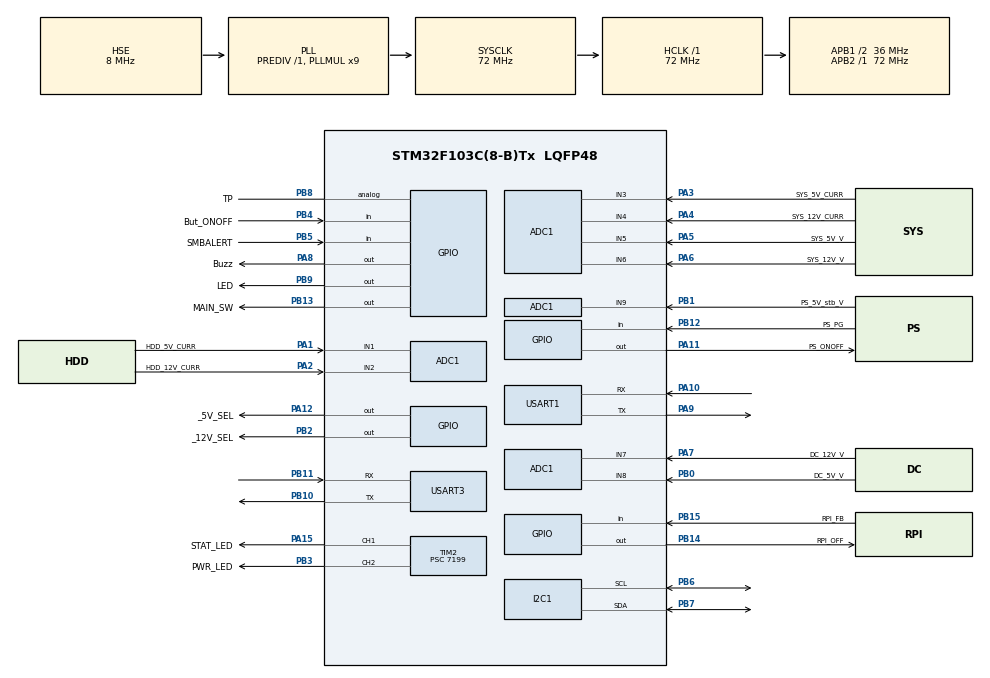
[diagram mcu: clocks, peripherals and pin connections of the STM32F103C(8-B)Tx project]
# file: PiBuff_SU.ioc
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ADC1.Channel-0\#ChannelRegularConversion=ADC_CHANNEL_TEMPSENSOR
ADC1.Channel-1\#ChannelRegularConversion=ADC_CHANNEL_1
ADC1.Channel-2\#ChannelRegularConversion=ADC_CHANNEL_2
ADC1.Channel-3\#ChannelRegularConversion=ADC_CHANNEL_3
ADC1.Channel-4\#ChannelRegularConversion=ADC_CHANNEL_4
ADC1.Channel-5\#ChannelRegularConversion=ADC_CHANNEL_5
ADC1.Channel-6\#ChannelRegularConversion=ADC_CHANNEL_6
ADC1.Channel-7\#ChannelRegularConversion=ADC_CHANNEL_7
ADC1.Channel-8\#ChannelRegularConversion=ADC_CHANNEL_8
ADC1.Channel-9\#ChannelRegularConversion=ADC_CHANNEL_9
ADC1.ContinuousConvMode=ENABLE
ADC1.NbrOfConversion=10
ADC1.NbrOfConversionFlag=1
ADC1.Rank-0\#ChannelRegularConversion=1
ADC1.Rank-1\#ChannelRegularConversion=2
ADC1.Rank-2\#ChannelRegularConversion=3
ADC1.Rank-3\#ChannelRegularConversion=4
ADC1.Rank-4\#ChannelRegularConversion=5
ADC1.Rank-5\#ChannelRegularConversion=6
ADC1.Rank-6\#ChannelRegularConversion=7
ADC1.Rank-7\#ChannelRegularConversion=8
ADC1.Rank-8\#ChannelRegularConversion=9
ADC1.Rank-9\#ChannelRegularConversion=10
ADC1.SamplingTime-0\#ChannelRegularConversion=ADC_SAMPLETIME_239CYCLES_5
ADC1.SamplingTime-1\#ChannelRegularConversion=ADC_SAMPLETIME_1CYCLE_5
ADC1.SamplingTime-2\#ChannelRegularConversion=ADC_SAMPLETIME_1CYCLE_5
ADC1.SamplingTime-3\#ChannelRegularConversion=ADC_SAMPLETIME_1CYCLE_5
ADC1.SamplingTime-4\#ChannelRegularConversion=ADC_SAMPLETIME_1CYCLE_5
ADC1.SamplingTime-5\#ChannelRegularConversion=ADC_SAMPLETIME_1CYCLE_5
ADC1.SamplingTime-6\#ChannelRegularConversion=ADC_SAMPLETIME_1CYCLE_5
ADC1.SamplingTime-7\#ChannelRegularConversion=ADC_SAMPLETIME_1CYCLE_5
ADC1.SamplingTime-8\#ChannelRegularConversion=ADC_SAMPLETIME_1CYCLE_5
ADC1.SamplingTime-9\#ChannelRegularConversion=ADC_SAMPLETIME_1CYCLE_5
ADC1.master=1
Dma.ADC1.0.Direction=DMA_PERIPH_TO_MEMORY
Dma.ADC1.0.Instance=DMA1_Channel1
Dma.ADC1.0.MemDataAlignment=DMA_MDATAALIGN_WORD
Dma.ADC1.0.MemInc=DMA_MINC_ENABLE
Dma.ADC1.0.Mode=DMA_CIRCULAR
Dma.ADC1.0.PeriphDataAlignment=DMA_PDATAALIGN_WORD
Dma.ADC1.0.PeriphInc=DMA_PINC_DISABLE
Dma.ADC1.0.Priority=DMA_PRIORITY_LOW
Dma.Request0=ADC1
Dma.Request1=USART3_TX
Dma.USART3_TX.1.Direction=DMA_MEMORY_TO_PERIPH
Dma.USART3_TX.1.Instance=DMA1_Channel2
Dma.USART3_TX.1.MemDataAlignment=DMA_MDATAALIGN_BYTE
Dma.USART3_TX.1.MemInc=DMA_MINC_ENABLE
Dma.USART3_TX.1.Mode=DMA_NORMAL
Dma.USART3_TX.1.PeriphDataAlignment=DMA_PDATAALIGN_BYTE
Dma.USART3_TX.1.PeriphInc=DMA_PINC_DISABLE
Dma.USART3_TX.1.Priority=DMA_PRIORITY_LOW
I2C1.I2C_Mode=I2C_Fast
Mcu.Family=STM32F1
Mcu.Name=STM32F103C(8-B)Tx
Mcu.Package=LQFP48
NVIC.DMA1_Channel1_IRQn=true\:0\:0\:false\:false\:true\:false\:true
NVIC.DMA1_Channel2_IRQn=true\:0\:0\:false\:false\:true\:false\:true
NVIC.PriorityGroup=NVIC_PRIORITYGROUP_4
NVIC.RCC_IRQn=true\:0\:0\:false\:false\:true\:true\:false
NVIC.TIM2_IRQn=true\:0\:0\:false\:false\:true\:true\:true
NVIC.USART1_IRQn=true\:0\:0\:false\:false\:true\:true\:true
NVIC.USART3_IRQn=true\:0\:0\:false\:false\:true\:true\:true
PA0-WKUP.Mode=SYS_WakeUp0
PA0-WKUP.Signal=SYS_WKUP
PA1.GPIO_Label=HDD_5V_CURR
PA1.Signal=ADCx_IN1
PA10.Mode=Asynchronous
PA10.Signal=USART1_RX
PA11.GPIO_Label=PS_ONOFF
PA11.Signal=GPIO_Output
PA12.GPIO_Label=_5V_SEL
PA12.Signal=GPIO_Output
PA13.Mode=Serial_Wire
PA13.Signal=SYS_JTMS-SWDIO
PA14.Mode=Serial_Wire
PA14.Signal=SYS_JTCK-SWCLK
PA15.GPIO_Label=STAT_LED
PA15.Signal=S_TIM2_CH1_ETR
PA2.GPIO_Label=HDD_12V_CURR
PA2.Signal=ADCx_IN2
PA3.GPIO_Label=SYS_5V_CURR
PA3.Signal=ADCx_IN3
PA4.GPIO_Label=SYS_12V_CURR
PA4.Signal=ADCx_IN4
PA5.GPIO_Label=SYS_5V_V
PA5.Signal=ADCx_IN5
PA6.GPIO_Label=SYS_12V_V
PA6.Signal=ADCx_IN6
PA7.GPIO_Label=DC_12V_V
PA7.Signal=ADCx_IN7
PA8.GPIO_Label=Buzz
PA8.Signal=GPIO_Output
PA9.Mode=Asynchronous
PA9.Signal=USART1_TX
PB0.GPIO_Label=DC_5V_V
PB0.Signal=ADCx_IN8
PB1.GPIO_Label=PS_5V_stb_V
PB1.Signal=ADCx_IN9
PB10.Mode=Asynchronous
PB10.Signal=USART3_TX
PB11.Mode=Asynchronous
PB11.Signal=USART3_RX
PB12.GPIO_Label=PS_PG
PB12.Signal=GPIO_Input
PB13.GPIO_Label=MAIN_SW
PB13.Signal=GPIO_Output
PB14.GPIO_Label=RPI_OFF
PB14.Signal=GPIO_Output
PB15.GPIO_Label=RPI_FB
PB15.Signal=GPIO_Input
PB2.GPIO_Label=_12V_SEL
PB2.Signal=GPIO_Output
PB3.GPIO_Label=PWR_LED
PB3.Signal=S_TIM2_CH2
PB4.GPIO_Label=But_ONOFF
PB4.Signal=GPIO_Input
PB5.GPIO_Label=SMBALERT
PB5.Signal=GPIO_Input
PB6.Mode=I2C
PB6.Signal=I2C1_SCL
PB7.Mode=I2C
PB7.Signal=I2C1_SDA
PB8.GPIO_Label=TP
PB8.Signal=GPIO_Analog
PB9.GPIO_Label=LED
PB9.Signal=GPIO_Output
PD0-OSC_IN.Mode=HSE-External-Oscillator
PD0-OSC_IN.Signal=RCC_OSC_IN
PD1-OSC_OUT.Mode=HSE-External-Oscillator
PD1-OSC_OUT.Signal=RCC_OSC_OUT
ProjectManager.HeapSize=0x200
ProjectManager.StackSize=0x400
ProjectManager.TargetToolchain=STM32CubeIDE
RCC.ADCPresc=RCC_ADCPCLK2_DIV6
RCC.AHBFreq_Value=72000000
RCC.APB1CLKDivider=RCC_HCLK_DIV2
RCC.APB1Freq_Value=36000000
RCC.APB1TimFreq_Value=72000000
RCC.APB2Freq_Value=72000000
RCC.APB2TimFreq_Value=72000000
RCC.HCLKFreq_Value=72000000
RCC.PLLMUL=RCC_PLL_MUL9
RCC.PLLSourceVirtual=RCC_PLLSOURCE_HSE
RCC.SYSCLKFreq_VALUE=72000000
RCC.SYSCLKSource=RCC_SYSCLKSOURCE_PLLCLK
RCC.USBFreq_Value=72000000
SH.ADCx_IN1.0=ADC1_IN1,IN1
SH.ADCx_IN2.0=ADC1_IN2,IN2
SH.ADCx_IN3.0=ADC1_IN3,IN3
SH.ADCx_IN4.0=ADC1_IN4,IN4
SH.ADCx_IN5.0=ADC1_IN5,IN5
SH.ADCx_IN6.0=ADC1_IN6,IN6
SH.ADCx_IN7.0=ADC1_IN7,IN7
SH.ADCx_IN8.0=ADC1_IN8,IN8
SH.ADCx_IN9.0=ADC1_IN9,IN9
SH.S_TIM2_CH1_ETR.0=TIM2_CH1,PWM Generation1 CH1
SH.S_TIM2_CH2.0=TIM2_CH2,PWM Generation2 CH2
TIM2.Channel-PWM\ Generation1\ CH1=TIM_CHANNEL_1
TIM2.Channel-PWM\ Generation2\ CH2=TIM_CHANNEL_2
TIM2.OCPolarity_1=TIM_OCPOLARITY_LOW
TIM2.OCPolarity_2=TIM_OCPOLARITY_LOW
TIM2.Period=200
TIM2.Prescaler=7199
USART1.VirtualMode=VM_ASYNC
USART3.VirtualMode=VM_ASYNC
VP_ADC1_TempSens_Input.Mode=IN-TempSens
VP_IWDG_VS_IWDG.Mode=IWDG_Activate
VP_TIM2_VS_ClockSourceINT.Mode=Internal
board=custom

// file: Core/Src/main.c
/* USER CODE BEGIN Header */
/**
  ******************************************************************************
  * @file           : main.c
  * @brief          : Main program body
  ******************************************************************************
  * @attention
  *
  * <h2><center>&copy; Copyright (c) 2021 STMicroelectronics.
  * All rights reserved.</center></h2>
  *
  * This software component is licensed by ST under BSD 3-Clause license,
  * the "License"; You may not use this file except in compliance with the
  * License. You may obtain a copy of the License at:
  *                        opensource.org/licenses/BSD-3-Clause
  *
  ******************************************************************************
  */
/* USER CODE END Header */
#include "main.h"
#include "buffsu.h"

ADC_HandleTypeDef hadc1;
DMA_HandleTypeDef hdma_adc1;

I2C_HandleTypeDef hi2c1;

IWDG_HandleTypeDef hiwdg;

TIM_HandleTypeDef htim2;

UART_HandleTypeDef huart1;
UART_HandleTypeDef huart3;
DMA_HandleTypeDef hdma_usart3_tx;

void SystemClock_Config(void);
static void MX_GPIO_Init(void);
static void MX_DMA_Init(void);
static void MX_ADC1_Init(void);
static void MX_I2C1_Init(void);
static void MX_IWDG_Init(void);
static void MX_USART1_UART_Init(void);
static void MX_USART3_UART_Init(void);

#if !defined(GPIO)
static void MX_TIM2_Init(void);
#endif

int main(void)
{

  /* MCU Configuration--------------------------------------------------------*/

  /* Reset of all peripherals, Initializes the Flash interface and the Systick. */
  HAL_Init();

  /* Configure the system clock */
  SystemClock_Config();

  /* Initialize all configured peripherals */
  MX_GPIO_Init();
  MX_DMA_Init();
  MX_ADC1_Init();
  MX_I2C1_Init();
//  MX_IWDG_Init();
  MX_USART1_UART_Init();
  MX_USART3_UART_Init();

#if !defined(GPIO)
  MX_TIM2_Init();
  HAL_TIM_Base_Start(&htim2);
#endif
  /* USER CODE BEGIN 2 */
  BuffSU_Loop();
  /* USER CODE END 2 */

  /* Infinite loop */
  while (1)
  {

  }
}

void SystemClock_Config(void)
{
  RCC_OscInitTypeDef RCC_OscInitStruct = {0};
  RCC_ClkInitTypeDef RCC_ClkInitStruct = {0};
  RCC_PeriphCLKInitTypeDef PeriphClkInit = {0};

  /** Initializes the RCC Oscillators according to the specified parameters
  * in the RCC_OscInitTypeDef structure.
  */
  RCC_OscInitStruct.OscillatorType = RCC_OSCILLATORTYPE_LSI|RCC_OSCILLATORTYPE_HSE;
  RCC_OscInitStruct.HSEState = RCC_HSE_ON;
  RCC_OscInitStruct.HSEPredivValue = RCC_HSE_PREDIV_DIV1;
  RCC_OscInitStruct.HSIState = RCC_HSI_ON;
  RCC_OscInitStruct.LSIState = RCC_LSI_ON;
  RCC_OscInitStruct.PLL.PLLState = RCC_PLL_ON;
  RCC_OscInitStruct.PLL.PLLSource = RCC_PLLSOURCE_HSE;
  RCC_OscInitStruct.PLL.PLLMUL = RCC_PLL_MUL9;
  if (HAL_RCC_OscConfig(&RCC_OscInitStruct) != HAL_OK)
  {
    Error_Handler();
  }
  /** Initializes the CPU, AHB and APB buses clocks
  */
  RCC_ClkInitStruct.ClockType = RCC_CLOCKTYPE_HCLK|RCC_CLOCKTYPE_SYSCLK
                              |RCC_CLOCKTYPE_PCLK1|RCC_CLOCKTYPE_PCLK2;
  RCC_ClkInitStruct.SYSCLKSource = RCC_SYSCLKSOURCE_PLLCLK;
  RCC_ClkInitStruct.AHBCLKDivider = RCC_SYSCLK_DIV1;
  RCC_ClkInitStruct.APB1CLKDivider = RCC_HCLK_DIV2;
  RCC_ClkInitStruct.APB2CLKDivider = RCC_HCLK_DIV1;

  if (HAL_RCC_ClockConfig(&RCC_ClkInitStruct, FLASH_LATENCY_2) != HAL_OK)
  {
    Error_Handler();
  }
  PeriphClkInit.PeriphClockSelection = RCC_PERIPHCLK_ADC;
  PeriphClkInit.AdcClockSelection = RCC_ADCPCLK2_DIV6;
  if (HAL_RCCEx_PeriphCLKConfig(&PeriphClkInit) != HAL_OK)
  {
    Error_Handler();
  }
}

static void MX_ADC1_Init(void)
{

  ADC_ChannelConfTypeDef sConfig = {0};

  /** Common config
  */
  hadc1.Instance = ADC1;
  hadc1.Init.ScanConvMode = ADC_SCAN_ENABLE;
  hadc1.Init.ContinuousConvMode = ENABLE;
  hadc1.Init.DiscontinuousConvMode = DISABLE;
  hadc1.Init.ExternalTrigConv = ADC_SOFTWARE_START;
  hadc1.Init.DataAlign = ADC_DATAALIGN_RIGHT;
  hadc1.Init.NbrOfConversion = 10;
  if (HAL_ADC_Init(&hadc1) != HAL_OK)
  {
    Error_Handler();
  }
  /** Configure Regular Channel
  */
  sConfig.Channel = ADC_CHANNEL_TEMPSENSOR;
  sConfig.Rank = ADC_REGULAR_RANK_1;
  sConfig.SamplingTime = ADC_SAMPLETIME_239CYCLES_5;
  if (HAL_ADC_ConfigChannel(&hadc1, &sConfig) != HAL_OK)
  {
    Error_Handler();
  }
  /** Configure Regular Channel
  */
  sConfig.Channel = ADC_CHANNEL_1;
  sConfig.Rank = ADC_REGULAR_RANK_2;
  sConfig.SamplingTime = ADC_SAMPLETIME_1CYCLE_5;
  if (HAL_ADC_ConfigChannel(&hadc1, &sConfig) != HAL_OK)
  {
    Error_Handler();
  }
  /** Configure Regular Channel
  */
  sConfig.Channel = ADC_CHANNEL_2;
  sConfig.Rank = ADC_REGULAR_RANK_3;
  if (HAL_ADC_ConfigChannel(&hadc1, &sConfig) != HAL_OK)
  {
    Error_Handler();
  }
  /** Configure Regular Channel
  */
  sConfig.Channel = ADC_CHANNEL_3;
  sConfig.Rank = ADC_REGULAR_RANK_4;
  if (HAL_ADC_ConfigChannel(&hadc1, &sConfig) != HAL_OK)
  {
    Error_Handler();
  }
  /** Configure Regular Channel
  */
  sConfig.Channel = ADC_CHANNEL_4;
  sConfig.Rank = ADC_REGULAR_RANK_5;
  if (HAL_ADC_ConfigChannel(&hadc1, &sConfig) != HAL_OK)
  {
    Error_Handler();
  }
  /** Configure Regular Channel
  */
  sConfig.Channel = ADC_CHANNEL_5;
  sConfig.Rank = ADC_REGULAR_RANK_6;
  if (HAL_ADC_ConfigChannel(&hadc1, &sConfig) != HAL_OK)
  {
    Error_Handler();
  }
  /** Configure Regular Channel
  */
  sConfig.Channel = ADC_CHANNEL_6;
  sConfig.Rank = ADC_REGULAR_RANK_7;
  if (HAL_ADC_ConfigChannel(&hadc1, &sConfig) != HAL_OK)
  {
    Error_Handler();
  }
  /** Configure Regular Channel
  */
  sConfig.Channel = ADC_CHANNEL_7;
  sConfig.Rank = ADC_REGULAR_RANK_8;
  if (HAL_ADC_ConfigChannel(&hadc1, &sConfig) != HAL_OK)
  {
    Error_Handler();
  }
  /** Configure Regular Channel
  */
  sConfig.Channel = ADC_CHANNEL_8;
  sConfig.Rank = ADC_REGULAR_RANK_9;
  if (HAL_ADC_ConfigChannel(&hadc1, &sConfig) != HAL_OK)
  {
    Error_Handler();
  }
  /** Configure Regular Channel
  */
  sConfig.Channel = ADC_CHANNEL_9;
  sConfig.Rank = ADC_REGULAR_RANK_10;
  if (HAL_ADC_ConfigChannel(&hadc1, &sConfig) != HAL_OK)
  {
    Error_Handler();
  }

}

static void MX_I2C1_Init(void)
{

  hi2c1.Instance = I2C1;
  hi2c1.Init.ClockSpeed = 400000;
  hi2c1.Init.DutyCycle = I2C_DUTYCYCLE_2;
  hi2c1.Init.OwnAddress1 = 0;
  hi2c1.Init.AddressingMode = I2C_ADDRESSINGMODE_7BIT;
  hi2c1.Init.DualAddressMode = I2C_DUALADDRESS_DISABLE;
  hi2c1.Init.OwnAddress2 = 0;
  hi2c1.Init.GeneralCallMode = I2C_GENERALCALL_DISABLE;
  hi2c1.Init.NoStretchMode = I2C_NOSTRETCH_DISABLE;
  if (HAL_I2C_Init(&hi2c1) != HAL_OK)
  {
    Error_Handler();
  }

}

static void MX_IWDG_Init(void)
{

  hiwdg.Instance = IWDG;
  hiwdg.Init.Prescaler = IWDG_PRESCALER_4;
  hiwdg.Init.Reload = 4095;
  if (HAL_IWDG_Init(&hiwdg) != HAL_OK)
  {
    Error_Handler();
  }

}

#if !defined(GPIO)
static void MX_TIM2_Init(void)
{

  TIM_ClockConfigTypeDef sClockSourceConfig = {0};
  TIM_MasterConfigTypeDef sMasterConfig = {0};
  TIM_OC_InitTypeDef sConfigOC = {0};

  htim2.Instance = TIM2;
  htim2.Init.Prescaler = 537;
  htim2.Init.CounterMode = TIM_COUNTERMODE_UP;
  htim2.Init.Period = 237;
  htim2.Init.ClockDivision = TIM_CLOCKDIVISION_DIV1;
  htim2.Init.AutoReloadPreload = TIM_AUTORELOAD_PRELOAD_DISABLE;
  if (HAL_TIM_Base_Init(&htim2) != HAL_OK)
  {
    Error_Handler();
  }
  sClockSourceConfig.ClockSource = TIM_CLOCKSOURCE_INTERNAL;
  if (HAL_TIM_ConfigClockSource(&htim2, &sClockSourceConfig) != HAL_OK)
  {
    Error_Handler();
  }
  if (HAL_TIM_PWM_Init(&htim2) != HAL_OK)
  {
    Error_Handler();
  }
  sMasterConfig.MasterOutputTrigger = TIM_TRGO_RESET;
  sMasterConfig.MasterSlaveMode = TIM_MASTERSLAVEMODE_DISABLE;
  if (HAL_TIMEx_MasterConfigSynchronization(&htim2, &sMasterConfig) != HAL_OK)
  {
    Error_Handler();
  }
  sConfigOC.OCMode = TIM_OCMODE_PWM1;
  sConfigOC.Pulse = 0;
  sConfigOC.OCPolarity = TIM_OCPOLARITY_HIGH;
  sConfigOC.OCFastMode = TIM_OCFAST_DISABLE;
  if (HAL_TIM_PWM_ConfigChannel(&htim2, &sConfigOC, TIM_CHANNEL_1) != HAL_OK)
  {
    Error_Handler();
  }
  if (HAL_TIM_PWM_ConfigChannel(&htim2, &sConfigOC, TIM_CHANNEL_2) != HAL_OK)
  {
    Error_Handler();
  }
  HAL_TIM_MspPostInit(&htim2);

}
#endif
static void MX_USART1_UART_Init(void)
{

  huart1.Instance = USART1;
  huart1.Init.BaudRate = 115200;
  huart1.Init.WordLength = UART_WORDLENGTH_8B;
  huart1.Init.StopBits = UART_STOPBITS_1;
  huart1.Init.Parity = UART_PARITY_NONE;
  huart1.Init.Mode = UART_MODE_TX_RX;
  huart1.Init.HwFlowCtl = UART_HWCONTROL_NONE;
  huart1.Init.OverSampling = UART_OVERSAMPLING_16;
  if (HAL_UART_Init(&huart1) != HAL_OK)
  {
    Error_Handler();
  }

}

static void MX_USART3_UART_Init(void)
{

  huart3.Instance = USART3;
  huart3.Init.BaudRate = 115200;
  huart3.Init.WordLength = UART_WORDLENGTH_8B;
  huart3.Init.StopBits = UART_STOPBITS_1;
  huart3.Init.Parity = UART_PARITY_NONE;
  huart3.Init.Mode = UART_MODE_TX_RX;
  huart3.Init.HwFlowCtl = UART_HWCONTROL_NONE;
  huart3.Init.OverSampling = UART_OVERSAMPLING_16;
  if (HAL_UART_Init(&huart3) != HAL_OK)
  {
    Error_Handler();
  }

}

static void MX_DMA_Init(void)
{

  /* DMA controller clock enable */
  __HAL_RCC_DMA1_CLK_ENABLE();

  /* DMA interrupt init */
  /* DMA1_Channel1_IRQn interrupt configuration */
  HAL_NVIC_SetPriority(DMA1_Channel1_IRQn, 0, 0);
  HAL_NVIC_EnableIRQ(DMA1_Channel1_IRQn);
  /* DMA1_Channel2_IRQn interrupt configuration */
  HAL_NVIC_SetPriority(DMA1_Channel2_IRQn, 0, 0);
  HAL_NVIC_EnableIRQ(DMA1_Channel2_IRQn);

}

static void MX_GPIO_Init(void)
{
  GPIO_InitTypeDef GPIO_InitStruct = {0};

  /* GPIO Ports Clock Enable */
  __HAL_RCC_GPIOD_CLK_ENABLE();
  __HAL_RCC_GPIOA_CLK_ENABLE();
  __HAL_RCC_GPIOB_CLK_ENABLE();

  /*Configure GPIO pin Output Level */
  HAL_GPIO_WritePin(GPIOB, _12V_SEL_Pin|MAIN_SW_Pin|RPI_OFF_Pin|LED_Pin, GPIO_PIN_RESET);

  /*Configure GPIO pin Output Level */
  HAL_GPIO_WritePin(GPIOA, Buzz_Pin|PS_ONOFF_Pin|_5V_SEL_Pin, GPIO_PIN_RESET);

  /*Configure GPIO pins : _12V_SEL_Pin MAIN_SW_Pin RPI_OFF_Pin LED_Pin */
#if defined(GPIO)
  GPIO_InitStruct.Pin = _12V_SEL_Pin|MAIN_SW_Pin|RPI_OFF_Pin|LED_Pin|PWR_LED_Pin;
#else
  GPIO_InitStruct.Pin = _12V_SEL_Pin|MAIN_SW_Pin|RPI_OFF_Pin|LED_Pin;
#endif

  GPIO_InitStruct.Mode = GPIO_MODE_OUTPUT_PP;
  GPIO_InitStruct.Pull = GPIO_NOPULL;
  GPIO_InitStruct.Speed = GPIO_SPEED_FREQ_LOW;
  HAL_GPIO_Init(GPIOB, &GPIO_InitStruct);

  /*Configure GPIO pins : PS_PG_Pin RPI_FB_Pin But_ONOFF_Pin SMBALERT_Pin */
  GPIO_InitStruct.Pin = PS_PG_Pin|RPI_FB_Pin|But_ONOFF_Pin|SMBALERT_Pin;
  GPIO_InitStruct.Mode = GPIO_MODE_INPUT;
  GPIO_InitStruct.Pull = GPIO_NOPULL;
  HAL_GPIO_Init(GPIOB, &GPIO_InitStruct);

  /*Configure GPIO pins : Buzz_Pin PS_ONOFF_Pin _5V_SEL_Pin */
#if defined(GPIO)
  GPIO_InitStruct.Pin = Buzz_Pin|PS_ONOFF_Pin|_5V_SEL_Pin|STAT_LED_Pin;
#else
  GPIO_InitStruct.Pin = Buzz_Pin|PS_ONOFF_Pin|_5V_SEL_Pin;
#endif

  GPIO_InitStruct.Mode = GPIO_MODE_OUTPUT_PP;
  GPIO_InitStruct.Pull = GPIO_NOPULL;
  GPIO_InitStruct.Speed = GPIO_SPEED_FREQ_LOW;
  HAL_GPIO_Init(GPIOA, &GPIO_InitStruct);

  /*Configure GPIO pin : TP_Pin */
  GPIO_InitStruct.Pin = TP_Pin;
  GPIO_InitStruct.Mode = GPIO_MODE_ANALOG;
  HAL_GPIO_Init(TP_GPIO_Port, &GPIO_InitStruct);

}

void Error_Handler(void)
{
  __disable_irq();
  while (1)
  {
  }
}
